# cslr_vlynq_001 register map
Vendor: Texas Instruments
Peripheral module from a debugger description file.
Registers are 32-bit, access per field, reset 0x0 unless marked. A register's access mark holds for its fields unless they carry their own. Offsets are as the file gives them; lines under a group give offsets from that group; [hi:lo] are bit positions; {n}, {i} and the like mark numbered series; 'fields as' and 'values as' point back to an identical list; <NAME> marks a mode.

## VLYNQ — High Frq Serial Inerface. (spec version: 2.5.1)
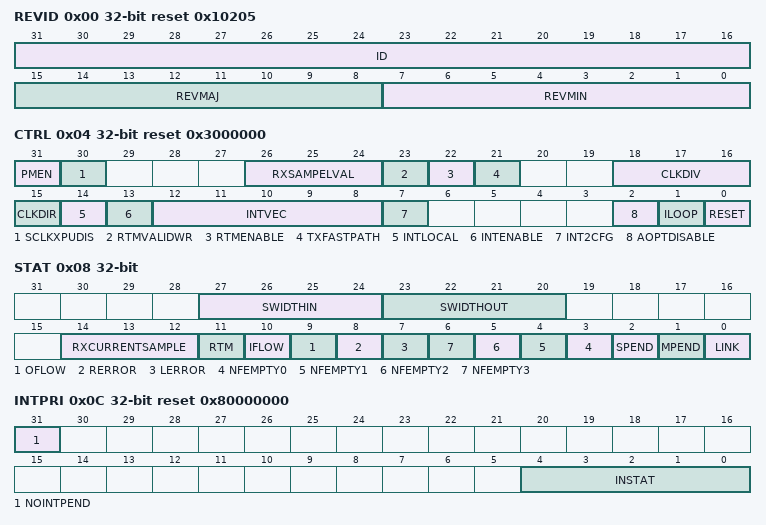
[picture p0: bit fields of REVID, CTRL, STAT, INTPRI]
0x00 REVID ro reset 0x10205 — Revision Register contains the major and minor revisions for the VLYNQ module.
  [31:16] ID — Unique Module ID
  [15:8] REVMAJ — Major Revision
  [7:0] REVMIN — Minor Revision
0x04 CTRL reset 0x3000000 — Control Register determines operation of the VLYNQ module.
  [31] PMEN rw — Power Management Enable
    0=DISABLE; 1=ENABLE
  [30] SCLKXPUDIS rw — Serial Clk pullup disable
    1=DISABLE; 0=ENABLE
  [26:24] RXSAMPELVAL rw — RTM Sample Value. Reset value is determined by the default_rxsampleval port.
  [23] RTMVALIDWR rw — RTM Valid Write Bit
    0=DISABLE; 1=ENABLE
  [22] RTMENABLE rw — RTM Enable Bit. Reset Value is determined by the default_rtmenable port.
    0=DISABLE; 1=ENABLE
  [21] TXFASTPATH rw — Tx Fast Path. When Set, the Fastest Path is chosen for the serial DATA.
    0=DISABLE; 1=ENABLE
  [18:16] CLKDIV rw — Serial Clock Output divider.
    0=ONE; 1=TWO; 2=THREE; 3=FOUR; 4=FIVE; 5=SIX; 6=SEVEN; 7=EIGHT
  [15] CLKDIR rw — Serial CLK direction. Reset value is determined by the default_clkdir port.
    0=INPUT; 1=OUTPUT
  [14] INTLOCAL rw — Interrupt Local.
    0=REMOTE; 1=LOCAL
  [13] INTENABLE rw — Interrupt Enable.
    0=DISABLE; 1=ENABLE
  [12:8] INTVEC rw — Interrupt Vector.
  [7] INT2CFG rw — Interrupt to Configuration Register.
    0=DISABLE; 1=ENABLE
  [2] AOPTDISABLE rw — Address Optimization Disable.
    1=DISABLE; 0=ENABLE
  [1] ILOOP rw — Internal Loop Back Enable.
    0=DISABLE; 1=ENABLE
  [0] RESET rw — S/W Reset
    0=DEASSERT; 1=ASSERT
0x08 STAT access not given (reset mask 0xFFFFF7FF) — Status Register is used to detect conditions that may be interest to the System Designer.
  [27:24] SWIDTHIN ro — Size of the inbound serial data.
  [23:20] SWIDTHOUT ro — Size of the outbound serial data.
  [14:12] RXCURRENTSAMPLE ro — Current RTM sample.
  [11] RTM ro — RTM enable. Reset value is determined by a tie-off with in vlynq_swd.v module
  [10] IFLOW ro — Inbound flow control.
  [9] OFLOW ro — Outbound flow control.
  [8] RERROR — Remote Error. (access WC)
  [7] LERROR — Local Error. (access WC)
  [n+3] NFEMPTY{n} ro (n=0..3) — FIFO {n} Not empty.
  [2] SPEND ro — Pending Slave Req.
  [1] MPEND ro — Pending Master Req.
  [0] LINK ro
0x0C INTPRI reset 0x80000000 — Interrupt Priority Vector Status/Clear Register
  [31] NOINTPEND ro — Interrupt Pending. A value of 1 means there are no pending Interrupts.
  [4:0] INSTAT rw
0x10 INTSTATCLR rw — Indicates the Unmasked interrupt status.
  [31:0] INTCLR — This Field Indicates the Unmasked status of each Interrupt.
0x14 INTPENDSET rw — Indicates the pending interrupt status when the intlocal bit in the Control Register is not set.
  [31:0] INTSET — This field indicates the Unmasked status of each pending Interrupt.
0x18 INTPTR — Interrupt Pointer Register
  [31:2] INTPTR rw — This field contains the address of the interrupt set register.
0x1C XAM — Tx Address Map Register.
  [31:2] TXADRMAP rw — Used to obtain the Zero relative transmit address.
{0x18+8i} RAMS{i} (i=1..4) — Rx Address Map Size {i} Register
  [31:2] RXADRSIZE{i} rw — Determine if rx packets are destined for the first of four mapped address region.
{0x1C+8i} RAMO{i} (i=1..4) — Rx Address Map Offset {i} Register
  [31:2] RXADROFFSET{i} rw — Used with the RXADDRMAPSIZE{i} Reg to determine the translated addr for serial data
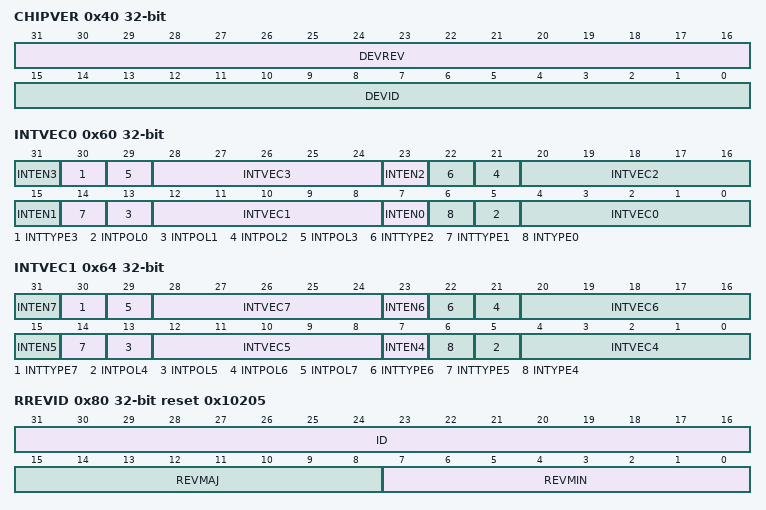
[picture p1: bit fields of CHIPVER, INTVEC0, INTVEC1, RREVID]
0x40 CHIPVER ro reset not defined — Reflect the value on the device_id and device_rev pins.
  [31:16] DEVREV — Device Revision.
  [15:0] DEVID — Device ID.
0x44 AUTNGO ro reset 0x10000 — Auto Negotiation Register
  [16] _2X — Indicate the version of Remote VLYNQ
0x48 MANNGO ro — Manual Negotiation Register
0x4C NGOSTAT ro reset 0x1 — Negotiation Status Register
  [0] MODE
0x60 INTVEC0 rw — Enables and Maps Interrupt sourced from vlynq_int_i[3:0] port.
  [8n+7] INTEN{n} (n=0..3) — Interrupt Enable
  [30] INTTYPE3 — Interrupt Type (Pulse/Level)
  [8n+5] INTPOL{n} (n=0..3) — Interrupt Polarity (Active Low/High)
  [8n+4:8n] INTVEC{n} (n=0..3) — Maps vlynq_int_i[{n}] pin to a bit in the Interrupt Pending/Set Reg.
  [22] INTTYPE2 — Interrupt Type (Pulse/Level)
  [14] INTTYPE1 — Interrupt Type (Pulse/Level)
  [6] INTYPE0 — Interrupt Type (Pulse/Level)
0x64 INTVEC1 rw — Enables and Maps Interrupt sourced from vlynq_int_i[7:4] port.
  [8n-25] INTEN{n} (n=4..7) — Interrupt Enable
  [30] INTTYPE7 — Interrupt Type (Pulse/Level)
  [8n-27] INTPOL{n} (n=4..7) — Interrupt Polarity (Active Low/High)
  [8n-28:8n-32] INTVEC{n} (n=4..7) — Maps vlynq_int_i[{n}] pin to a bit in the Interrupt Pending/Set Reg.
  [22] INTTYPE6 — Interrupt Type (Pulse/Level)
  [14] INTTYPE5 — Interrupt Type (Pulse/Level)
  [6] INTYPE4 — Interrupt Type (Pulse/Level)
0x80 RREVID ro reset 0x10205 — Remote Revision Register contains the major and minor revisions for the Remote VLYNQ .
  fields as REVID
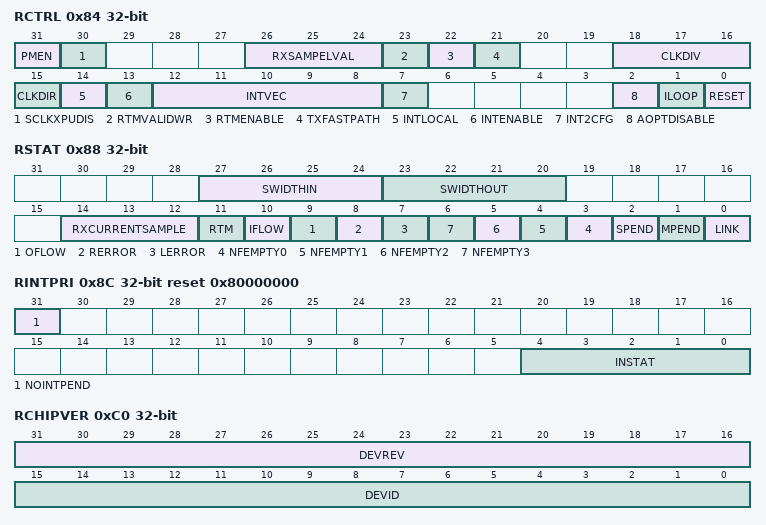
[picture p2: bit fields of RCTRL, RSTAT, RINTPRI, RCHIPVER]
0x84 RCTRL — Remote Control Register determines operation of the Remote VLYNQ module.
  fields as CTRL
0x88 RSTAT access not given — Remote Status Register is used to detect conditions of Remote VLYNQ that may be interest to the System Designer.
  fields as STAT
0x8C RINTPRI reset 0x80000000 — Remote Interrupt Priority Vector Status/Clear Register
  fields as INTPRI
0x90 RINTSTATCLR rw — Indicates the Unmasked interrupt status of Remote VLYNQ.
  fields as INTSTATCLR
0x94 RINTPENDSET rw — Indicates the pending interrupt status of Remote VLYNQ when the intlocal bit in the Remote Control Register is not set.
  fields as INTPENDSET
0x98 RINTPTR — Remote Interrupt Pointer Register
  fields as INTPTR
0x9C RXAM — Remote Tx Address Map Register.
  fields as XAM
{0x98+8i} RRAMS{i} (i=1..4) — Remote Rx Address Map Size {i} Register
  fields as RAMS1
{0x9C+8i} RRAMO{i} (i=1..4) — Remote Rx Address Map Offset {i} Register
  fields as RAMO1
0xC0 RCHIPVER ro reset not defined — Reflect the value on the device_id and device_rev pins of Remote VLYNQ.
  [31:16] DEVREV — Device Revision.
  [15:0] DEVID — Device ID.
0xC4 RAUTNGO ro reset 0x10000 — Remote Auto Negotiation Register
  [16] _2X — Indicate the version of Remote VLYNQ
0xC8 RMANNGO ro — Remote Manual Negotiation Register
0xCC RNGOSTAT ro reset 0x1 — Remote Negotiation Status Register
  [0] MODE
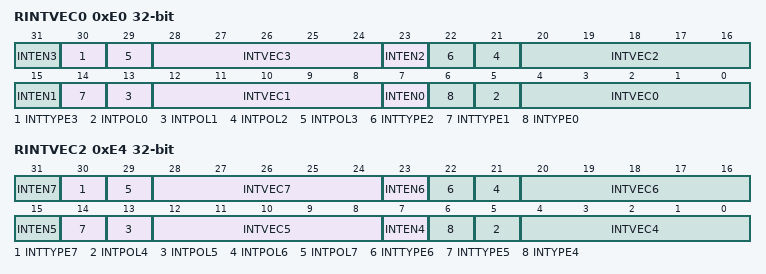
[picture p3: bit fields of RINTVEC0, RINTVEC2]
0xE0 RINTVEC0 rw — Enables and Maps Interrupt sourced from vlynq_int_i[3:0] port of Remote VLYNQ.
  fields as INTVEC0
0xE4 RINTVEC2 rw — Enables and Maps Interrupt sourced from vlynq_int_i[7:4] port of Remote VLYNQ.
  fields as INTVEC1
